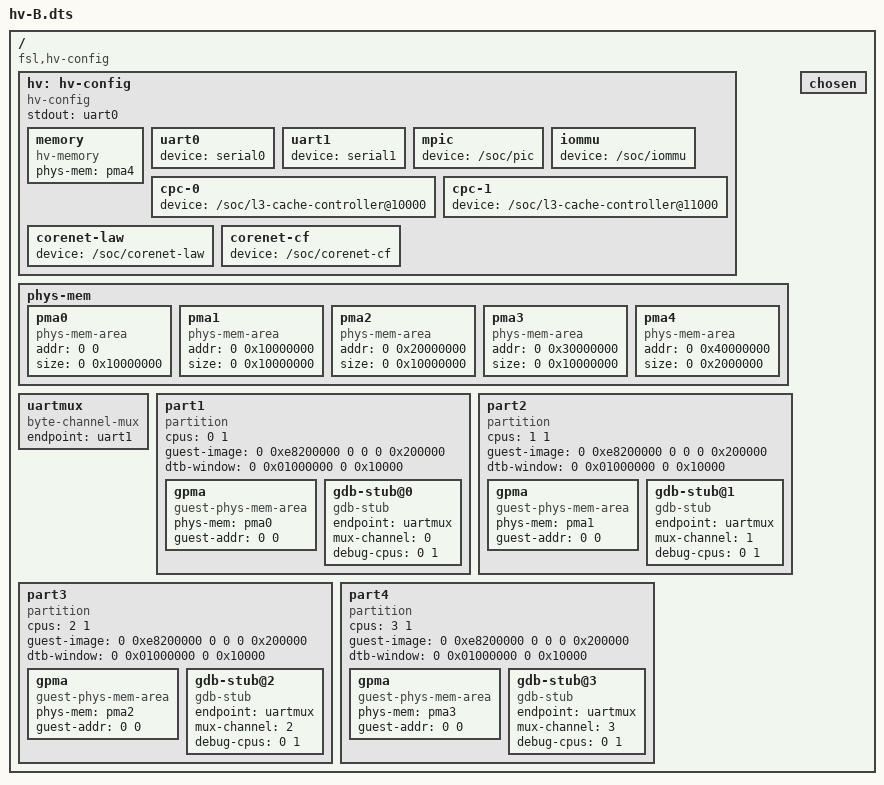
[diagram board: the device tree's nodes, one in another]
/*
 * Copyright (C) 2008,2009 Freescale Semiconductor, Inc.
 *
 * Redistribution and use in source and binary forms, with or without
 * modification, are permitted provided that the following conditions
 * are met:
 * 1. Redistributions of source code must retain the above copyright
 *    notice, this list of conditions and the following disclaimer.
 * 2. Redistributions in binary form must reproduce the above copyright
 *    notice, this list of conditions and the following disclaimer in the
 *    documentation and/or other materials provided with the distribution.
 *
 * THIS SOFTWARE IS PROVIDED BY THE AUTHOR "AS IS" AND ANY EXPRESS OR
 * IMPLIED WARRANTIES, INCLUDING, BUT NOT LIMITED TO, THE IMPLIED WARRANTIES
 * OF MERCHANTABILITY AND FITNESS FOR A PARTICULAR PURPOSE ARE DISCLAIMED.  IN
 * NO EVENT SHALL THE AUTHOR BE LIABLE FOR ANY DIRECT, INDIRECT, INCIDENTAL,
 * SPECIAL, EXEMPLARY, OR CONSEQUENTIAL DAMAGES (INCLUDING, BUT NOT LIMITED
 * TO, PROCUREMENT OF SUBSTITUTE GOODS OR SERVICES; LOSS OF USE, DATA, OR
 * PROFITS; OR BUSINESS INTERRUPTION) HOWEVER CAUSED AND ON ANY THEORY OF
 * LIABILITY, WHETHER IN CONTRACT, STRICT LIABILITY, OR TORT (INCLUDING
 * NEGLIGENCE OR OTHERWISE) ARISING IN ANY WAY OUT OF THE USE OF THIS
 * SOFTWARE, EVEN IF ADVISED OF THE POSSIBILITY OF SUCH DAMAGE.
 */

/dts-v1/;

/ {
	compatible = "fsl,hv-config";

	// =====================================================
	// Hypervisor Config
	// =====================================================
	hv: hv-config {
		compatible = "hv-config";
		stdout = <&uart0>;
		
		memory {
			compatible = "hv-memory";
			phys-mem = <&pma4>;
		};

		uart0: uart0 {
			device = "serial0";
		};

		uart1: uart1 {
			device = "serial1";
		};

		mpic {
			device = "/soc/pic";
		};

		iommu {
			device = "/soc/iommu";
		};

		cpc-0 {
			device = "/soc/l3-cache-controller@10000";
		};

		cpc-1 {
			device = "/soc/l3-cache-controller@11000";
		};

		corenet-law {
			device = "/soc/corenet-law";
		};

		corenet-cf {
			device = "/soc/corenet-cf";
		};
	};

	// =====================================================
	// Physical Memory Areas
	// =====================================================
	phys-mem {
		pma0:pma0 {
			compatible = "phys-mem-area";
			addr = <0 0>;
			size = <0 0x10000000>;
		};

		pma1:pma1 {
			compatible = "phys-mem-area";
			addr = <0 0x10000000>;
			size = <0 0x10000000>;
		};

		pma2:pma2 {
			compatible = "phys-mem-area";
			addr = <0 0x20000000>;
			size = <0 0x10000000>;
		};

		pma3:pma3 {
			compatible = "phys-mem-area";
			addr = <0 0x30000000>;
			size = <0 0x10000000>;
		};

		pma4:pma4 {
			compatible = "phys-mem-area";
			addr = <0 0x40000000>;
			size = <0 0x2000000>;
		};
	};

	uartmux: uartmux {
		compatible = "byte-channel-mux";
		endpoint = <&uart1>;
	};

	// =====================================================
	// Partition 1
	// =====================================================
	part1 {
		compatible = "partition";
		cpus = <0 1>;
		guest-image = <0 0xe8200000 0 0 0 0x200000>;
		dtb-window = <0 0x01000000 0 0x10000>;

		gpma {
			compatible = "guest-phys-mem-area";
			phys-mem = <&pma0>;
			guest-addr = <0 0>;
		};

		gdb-stub@0 {
			compatible = "gdb-stub", "debug-stub";
			endpoint = <&uartmux>;
			mux-channel = <0>;
			debug-cpus = <0 1>; //virtual cpu 0
		};
	};

	// =====================================================
	// Partition 2
	// =====================================================
	part2 {
		compatible = "partition";
		cpus = <1 1>;
		guest-image = <0 0xe8200000 0 0 0 0x200000>;
		dtb-window = <0 0x01000000 0 0x10000>;

		gpma {
			compatible = "guest-phys-mem-area";
			phys-mem = <&pma1>;
			guest-addr = <0 0>;
		};

		gdb-stub@1 {
			compatible = "gdb-stub", "debug-stub";
			endpoint = <&uartmux>;
			mux-channel = <1>;
			debug-cpus = <0 1>; //virtual cpu 0
		};
	};

	// =====================================================
	// Partition 3
	// =====================================================
	part3 {
		compatible = "partition";
		cpus = <2 1>;
		guest-image = <0 0xe8200000 0 0 0 0x200000>;
		dtb-window = <0 0x01000000 0 0x10000>;

		gpma {
			compatible = "guest-phys-mem-area";
			phys-mem = <&pma2>;
			guest-addr = <0 0>;
		};

		gdb-stub@2 {
			compatible = "gdb-stub", "debug-stub";
			endpoint = <&uartmux>;
			mux-channel = <2>;
			debug-cpus = <0 1>; //virtual cpu 0
		};
	};

	// =====================================================
	// Partition 4
	// =====================================================
	part4 {
		compatible = "partition";
		cpus = <3 1>;
		guest-image = <0 0xe8200000 0 0 0 0x200000>;
		dtb-window = <0 0x01000000 0 0x10000>;

		gpma {
			compatible = "guest-phys-mem-area";
			phys-mem = <&pma3>;
			guest-addr = <0 0>;
		};

		gdb-stub@3 {
			compatible = "gdb-stub", "debug-stub";
			endpoint = <&uartmux>;
			mux-channel = <3>;
			debug-cpus = <0 1>; //virtual cpu 0
		};
	};

	chosen {
	};
};
